AUTOSAR XML (schema 00048)
package /ComponentTypes
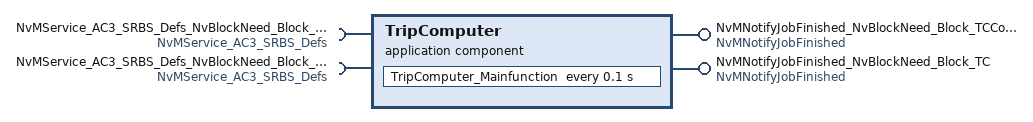
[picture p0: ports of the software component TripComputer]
  application sw component type TripComputer
    provide port NvMNotifyJobFinished_NvBlockNeed_Block_TCConfig: server-com-spec{operation=JobFinished, queue-length=1}, provided-interface=NvMNotifyJobFinished
    require port NvMService_AC3_SRBS_Defs_NvBlockNeed_Block_TCConfig: required-com-specs=[WriteBlock, SetRamBlockStatus, RestoreBlockDefaults, ReadBlock, InvalidateNvBlock, GetErrorStatus, EraseBlock], required-interface=NvMService_AC3_SRBS_Defs
    provide port NvMNotifyJobFinished_NvBlockNeed_Block_TC: server-com-spec{operation=JobFinished, queue-length=1}, provided-interface=NvMNotifyJobFinished
    require port NvMService_AC3_SRBS_Defs_NvBlockNeed_Block_TC: required-com-specs=[WriteBlock, SetRamBlockStatus, RestoreBlockDefaults, ReadBlock, InvalidateNvBlock, GetErrorStatus, EraseBlock], required-interface=NvMService_AC3_SRBS_Defs
    behavior TripComputer_InternalBehavior
      ar-typed-per-instance-memorys:
        data NvBlockNeed_Block_TCConfig_MirrorBlock: sw-calibration-access=READ-ONLY, type=NVMBlockTCConfig_Type
        data NvBlockNeed_Block_TC_MirrorBlock: sw-calibration-access=READ-ONLY, type=NVMBlockTC_Type
      init event TripComputer_InitEvent: start-on-event=TripComputer_Init
      timing event TMT_TripComputer_Mainfunction: start-on-event=TripComputer_Mainfunction, period=0.1
      operation invoked event OIT_NvMNotifyJobFinished_NvBlockNeed_Block_TC_JobFinished_NvMNotifyJobFinished_NvBlockNeed_Block_TC_JobFinished: start-on-event=NvMNotifyJobFinished_NvBlockNeed_Block_TC_JobFinished, operation=NvMNotifyJobFinished_NvBlockNeed_Block_TC.JobFinished
      operation invoked event OIT_NvMNotifyJobFinished_NvBlockNeed_Block_TCConfig_JobFinished_NvMNotifyJobFinished_NvBlockNeed_Block_TCConfig_JobFinished: start-on-event=NvMNotifyJobFinished_NvBlockNeed_Block_TCConfig_JobFinished, operation=NvMNotifyJobFinished_NvBlockNeed_Block_TCConfig.JobFinished
      4 x runnable:
        TripComputer_Init
        TripComputer_Mainfunction
          14 x sync call:
            SC_NvMService_AC3_SRBS_Defs_NvBlockNeed_Block_TC_EraseBlock: operation=NvMService_AC3_SRBS_Defs_NvBlockNeed_Block_TC.EraseBlock
            SC_NvMService_AC3_SRBS_Defs_NvBlockNeed_Block_TC_GetErrorStatus: operation=NvMService_AC3_SRBS_Defs_NvBlockNeed_Block_TC.GetErrorStatus
            SC_NvMService_AC3_SRBS_Defs_NvBlockNeed_Block_TC_InvalidateNvBlock: operation=NvMService_AC3_SRBS_Defs_NvBlockNeed_Block_TC.InvalidateNvBlock
            SC_NvMService_AC3_SRBS_Defs_NvBlockNeed_Block_TC_ReadBlock: operation=NvMService_AC3_SRBS_Defs_NvBlockNeed_Block_TC.ReadBlock
            SC_NvMService_AC3_SRBS_Defs_NvBlockNeed_Block_TC_RestoreBlockDefaults: operation=NvMService_AC3_SRBS_Defs_NvBlockNeed_Block_TC.RestoreBlockDefaults
            SC_NvMService_AC3_SRBS_Defs_NvBlockNeed_Block_TC_SetRamBlockStatus: operation=NvMService_AC3_SRBS_Defs_NvBlockNeed_Block_TC.SetRamBlockStatus
            SC_NvMService_AC3_SRBS_Defs_NvBlockNeed_Block_TC_WriteBlock: operation=NvMService_AC3_SRBS_Defs_NvBlockNeed_Block_TC.WriteBlock
            SC_NvMService_AC3_SRBS_Defs_NvBlockNeed_Block_TCConfig_EraseBlock: operation=NvMService_AC3_SRBS_Defs_NvBlockNeed_Block_TCConfig.EraseBlock
            SC_NvMService_AC3_SRBS_Defs_NvBlockNeed_Block_TCConfig_GetErrorStatus: operation=NvMService_AC3_SRBS_Defs_NvBlockNeed_Block_TCConfig.GetErrorStatus
            SC_NvMService_AC3_SRBS_Defs_NvBlockNeed_Block_TCConfig_InvalidateNvBlock: operation=NvMService_AC3_SRBS_Defs_NvBlockNeed_Block_TCConfig.InvalidateNvBlock
            SC_NvMService_AC3_SRBS_Defs_NvBlockNeed_Block_TCConfig_ReadBlock: operation=NvMService_AC3_SRBS_Defs_NvBlockNeed_Block_TCConfig.ReadBlock
            SC_NvMService_AC3_SRBS_Defs_NvBlockNeed_Block_TCConfig_RestoreBlockDefaults: operation=NvMService_AC3_SRBS_Defs_NvBlockNeed_Block_TCConfig.RestoreBlockDefaults
            SC_NvMService_AC3_SRBS_Defs_NvBlockNeed_Block_TCConfig_SetRamBlockStatus: operation=NvMService_AC3_SRBS_Defs_NvBlockNeed_Block_TCConfig.SetRamBlockStatus
            SC_NvMService_AC3_SRBS_Defs_NvBlockNeed_Block_TCConfig_WriteBlock: operation=NvMService_AC3_SRBS_Defs_NvBlockNeed_Block_TCConfig.WriteBlock
        NvMNotifyJobFinished_NvBlockNeed_Block_TC_JobFinished
        NvMNotifyJobFinished_NvBlockNeed_Block_TCConfig_JobFinished
      swc service dependency NvBlockNeed_Block_TC
        assigned-datas:
          role=ramBlock, used-data-element=NvBlockNeed_Block_TC_MirrorBlock
          role=defaultValue, used-parameter-element=NvBlockNeed_Block_TC_DefaultValue
        assigned-ports:
          port-prototype=NvMNotifyJobFinished_NvBlockNeed_Block_TC, role=NvMNotifyJobFinished
          port-prototype=NvMService_AC3_SRBS_Defs_NvBlockNeed_Block_TC, role=NvMService_AC3_SRBS_Defs
        service-needs:
          nv block needs NvBlockNeed_Block_TC: n-data-sets=0, ram-block-status-control=API, reliability=NO-PROTECTION, restore-at-start=true, store-at-shutdown=true
      swc service dependency NvBlockNeed_Block_TCConfig
        assigned-datas:
          role=ramBlock, used-data-element=NvBlockNeed_Block_TCConfig_MirrorBlock
          role=defaultValue, used-parameter-element=NvBlockNeed_Block_TCConfig_DefaultValue
        assigned-ports:
          port-prototype=NvMNotifyJobFinished_NvBlockNeed_Block_TCConfig, role=NvMNotifyJobFinished
          port-prototype=NvMService_AC3_SRBS_Defs_NvBlockNeed_Block_TCConfig, role=NvMService_AC3_SRBS_Defs
        service-needs:
          nv block needs NvBlockNeed_Block_TCConfig: n-data-sets=0, ram-block-status-control=API, reliability=NO-PROTECTION, restore-at-start=true, store-at-shutdown=true
      shared-parameters:
        parameter data prototype NvBlockNeed_Block_TCConfig_DefaultValue: sw-calibration-access=READ-WRITE, type=NVMBlockTCConfig_Type, init-value=constant-reference=NVMBlockTCConfigInit
        parameter data prototype NvBlockNeed_Block_TC_DefaultValue: sw-calibration-access=READ-WRITE, type=NVMBlockTC_Type, init-value=constant-reference=NVMBlockTCInit
  swc implementation TripComputer_Implementation: behavior=TripComputer_InternalBehavior
